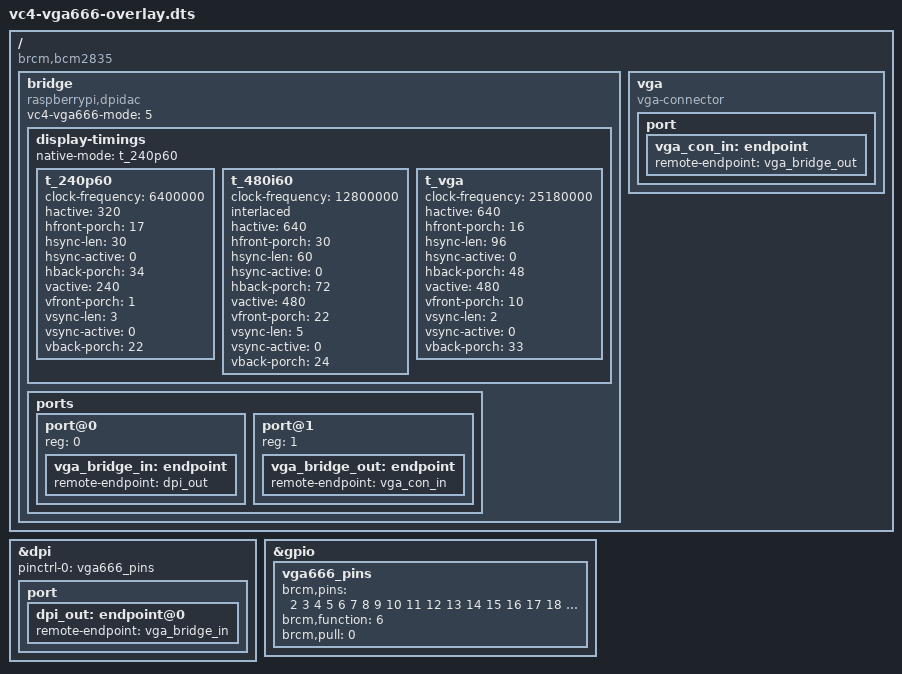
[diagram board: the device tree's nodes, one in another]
/dts-v1/;
/plugin/;

#include <dt-bindings/pinctrl/bcm2835.h>

/ {
	compatible = "brcm,bcm2835", "brcm,bcm2708", "brcm,bcm2709";

	fragment@0 {
		target-path = "/";
		__overlay__ {
			bridge: bridge {
				compatible = "raspberrypi,dpidac";
				#address-cells = <1>;
				#size-cells = <0>;

				vc4-vga666-mode = <5>;

				display-timings {
					native-mode = <&t_240p60>;

					t_240p60: t_240p60 {
						clock-frequency = <6400000>;
						hactive = <320>;
						hfront-porch = <17>;
						hsync-len = <30>;
						hsync-active = <0>;
						hback-porch = <34>;
						vactive = <240>;
						vfront-porch = <1>;
						vsync-len = <3>;
						vsync-active = <0>;
						vback-porch = <22>;
					};
					
					t_480i60: t_480i60 {
						clock-frequency = <12800000>;
						interlaced;
						hactive = <640>;
						hfront-porch = <30>;
						hsync-len = <60>;
						hsync-active = <0>;
						hback-porch = <72>;
						vactive = <480>;
						vfront-porch = <22>;
						vsync-len = <5>;
						vsync-active = <0>;
						vback-porch = <24>;
					};
					
					t_vga: t_vga {
						clock-frequency = <25180000>;
						hactive = <640>;
						hfront-porch = <16>;
						hsync-len = <96>;
						hsync-active = <0>;
						hback-porch = <48>;
						vactive = <480>;
						vfront-porch = <10>;
						vsync-len = <2>;
						vsync-active = <0>;
						vback-porch = <33>;
					};
				};

				ports {
					#address-cells = <1>;
					#size-cells = <0>;

					port@0 {
						reg = <0>;

						vga_bridge_in: endpoint {
							remote-endpoint = <&dpi_out>;
						};
					};

					port@1 {
						reg = <1>;

						vga_bridge_out: endpoint {
							remote-endpoint = <&vga_con_in>;
						};
					};
				};
			};

			vga {
				compatible = "vga-connector";

				port {
					vga_con_in: endpoint {
						remote-endpoint = <&vga_bridge_out>;
					};
				};
			};
		};
	};

	fragment@1 {
		target = <&dpi>;
		__overlay__  {
			status = "okay";
			port {
				dpi_out: endpoint@0 {
					remote-endpoint = <&vga_bridge_in>;
				};
			};
		};
	};

	fragment@2 {
		target = <&dpi>;
		__overlay__  {
			status = "okay";
			pinctrl-names = "default";
			pinctrl-0 = <&vga666_pins>;
		};
	};

	fragment@3 {
		target = <&gpio>;
		__overlay__ {
			vga666_pins: vga666_pins {
				brcm,pins = <2 3 4 5 6 7 8 9 10 11 12
					     13 14 15 16 17 18 19 20 21>;
				brcm,function = <6>;
				brcm,pull = <0>;
			};
		};
	};

	fragment@4 {
		target = <&dpi>;
		__dormant__  {
			status = "okay";
			pinctrl-names = "default";
			pinctrl-0 = <&vga666_mode6_pins>;
		};
	};

	fragment@5 {
		target = <&gpio>;
		__dormant__ {
			vga666_mode6_pins: vga666_mode6_pins {
				brcm,pins = <2 3 4 5 6 7 8 9 12 13 14
						 15 16 17 20 21 22 23 24 25>;
				brcm,function = <6>;
				brcm,pull = <0>;
			};
		};
	};

    fragment@6 {
		target = <&bridge>;
		__dormant__ {
			vc4-vga666-mode = <6>;
		};
	};

	__overrides__ {
		mode5 = <0>,"+0+1+2+3-4-5-6";
		mode6 = <0>,"+0+1-2-3+4+5+6";
	};
};
